# LM4F120E5QR register map
File version: 7944
Registers are 32-bit, read-write, no defined reset value unless marked. A register's access mark holds for its fields unless they carry their own. Offsets are from the block's base; [hi:lo] are bit positions.

## I2C0 — Register map for I2C0 peripheral
Base 0x40020000; register names take the prefix I2C0
Same registers: I2C1 0x40021000 (register names take the prefix I2C1), I2C2 0x40022000 (register names take the prefix I2C2), I2C3 0x40023000 (register names take the prefix I2C3)
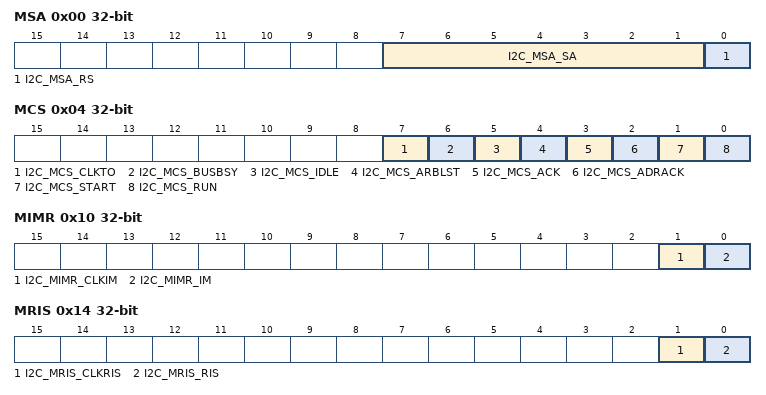
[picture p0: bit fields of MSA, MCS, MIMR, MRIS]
0x00 MSA — I2C Master Slave Address
  [7:1] I2C_MSA_SA — I2C Slave Address
  [0] I2C_MSA_RS — Receive not send
0x04 MCS — I2C Master Control/Status
  [7] I2C_MCS_CLKTO — Clock Timeout Error
  [6] I2C_MCS_BUSBSY — Bus Busy
  [5] I2C_MCS_IDLE — I2C Idle
  [4] I2C_MCS_ARBLST — Arbitration Lost
  [3] I2C_MCS_ACK — Data Acknowledge Enable
  [2] I2C_MCS_ADRACK — Acknowledge Address
  [1] I2C_MCS_START — Generate START
  [0] I2C_MCS_RUN — I2C Master Enable
0x04 MCS (I2C0_ALT view) — I2C Master Control/Status
  [3] I2C_MCS_DATACK — Acknowledge Data
  [2] I2C_MCS_STOP — Generate STOP
  [1] I2C_MCS_ERROR — Error
  [0] I2C_MCS_BUSY — I2C Busy
0x08 MDR — I2C Master Data
  [7:0] I2C_MDR_DATA — Data Transferred
0x0C MTPR — I2C Master Timer Period
  [6:0] I2C_MTPR_TPR — SCL Clock Period
0x10 MIMR — I2C Master Interrupt Mask
  [1] I2C_MIMR_CLKIM — Clock Timeout Interrupt Mask
  [0] I2C_MIMR_IM — Interrupt Mask
0x14 MRIS — I2C Master Raw Interrupt Status
  [1] I2C_MRIS_CLKRIS — Clock Timeout Raw Interrupt Status
  [0] I2C_MRIS_RIS — Raw Interrupt Status
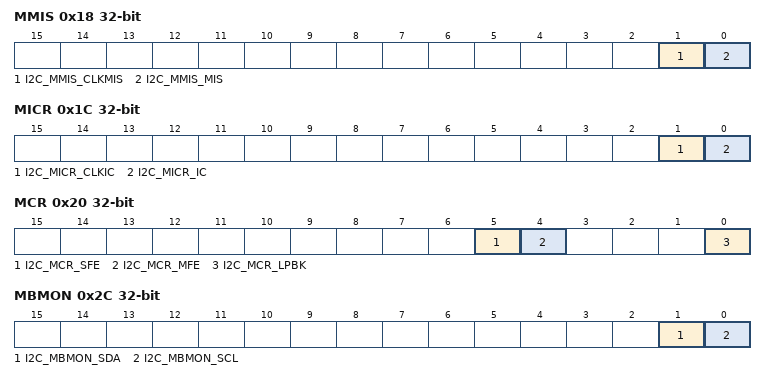
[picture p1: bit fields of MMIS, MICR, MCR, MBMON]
0x18 MMIS — I2C Master Masked Interrupt Status
  [1] I2C_MMIS_CLKMIS — Clock Timeout Masked Interrupt Status
  [0] I2C_MMIS_MIS — Masked Interrupt Status
0x1C MICR wo — I2C Master Interrupt Clear
  [1] I2C_MICR_CLKIC — Clock Timeout Interrupt Clear
  [0] I2C_MICR_IC — Interrupt Clear
0x20 MCR — I2C Master Configuration
  [5] I2C_MCR_SFE — I2C Slave Function Enable
  [4] I2C_MCR_MFE — I2C Master Function Enable
  [0] I2C_MCR_LPBK — I2C Loopback
0x24 MCLKOCNT — I2C Master Clock Low Timeout Count
  [7:0] I2C_MCLKOCNT_CNTL — I2C Master Count
0x2C MBMON — I2C Master Bus Monitor
  [1] I2C_MBMON_SDA — I2C SDA Status
  [0] I2C_MBMON_SCL — I2C SCL Status
0x800 SOAR — I2C Slave Own Address
  [6:0] I2C_SOAR_OAR
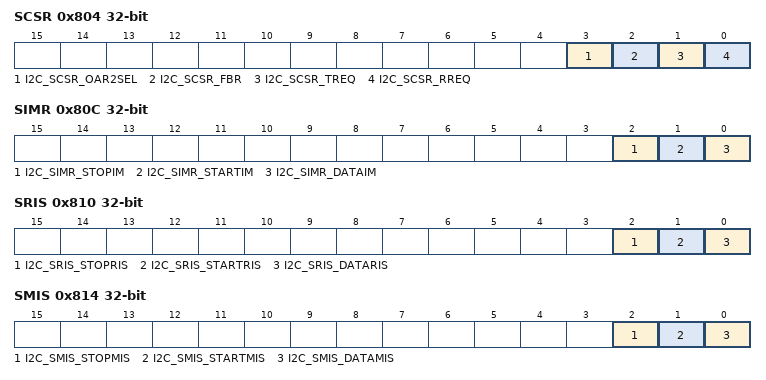
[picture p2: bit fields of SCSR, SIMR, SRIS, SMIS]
0x804 SCSR — I2C Slave Control/Status
  [3] I2C_SCSR_OAR2SEL — OAR2 Address Matched
  [2] I2C_SCSR_FBR — First Byte Received
  [1] I2C_SCSR_TREQ — Transmit Request
  [0] I2C_SCSR_RREQ — Receive Request
0x804 SCSR (I2C0_ALT view) — I2C Slave Control/Status
  [0] I2C_SCSR_DA — Device Active
0x808 SDR — I2C Slave Data
  [7:0] I2C_SDR_DATA — Data for Transfer
0x80C SIMR — I2C Slave Interrupt Mask
  [2] I2C_SIMR_STOPIM — Stop Condition Interrupt Mask
  [1] I2C_SIMR_STARTIM — Start Condition Interrupt Mask
  [0] I2C_SIMR_DATAIM — Data Interrupt Mask
0x810 SRIS — I2C Slave Raw Interrupt Status
  [2] I2C_SRIS_STOPRIS — Stop Condition Raw Interrupt Status
  [1] I2C_SRIS_STARTRIS — Start Condition Raw Interrupt Status
  [0] I2C_SRIS_DATARIS — Data Raw Interrupt Status
0x814 SMIS — I2C Slave Masked Interrupt Status
  [2] I2C_SMIS_STOPMIS — Stop Condition Masked Interrupt Status
  [1] I2C_SMIS_STARTMIS — Start Condition Masked Interrupt Status
  [0] I2C_SMIS_DATAMIS — Data Masked Interrupt Status
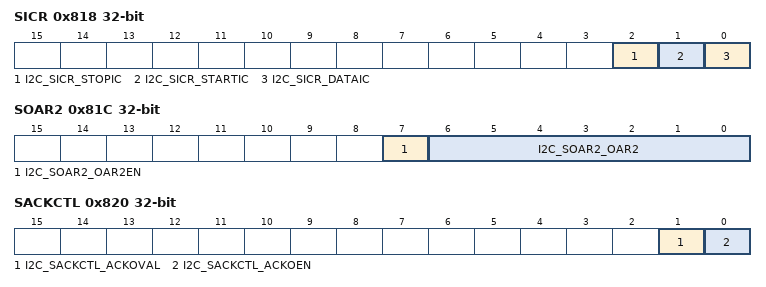
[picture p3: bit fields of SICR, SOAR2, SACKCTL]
0x818 SICR wo — I2C Slave Interrupt Clear
  [2] I2C_SICR_STOPIC — Stop Condition Interrupt Clear
  [1] I2C_SICR_STARTIC — Start Condition Interrupt Clear
  [0] I2C_SICR_DATAIC — Data Interrupt Clear
0x81C SOAR2 — I2C Slave Own Address 2
  [7] I2C_SOAR2_OAR2EN — I2C Slave Own Address 2 Enable
  [6:0] I2C_SOAR2_OAR2 — I2C Slave Own Address 2
0x820 SACKCTL — I2C ACK Control
  [1] I2C_SACKCTL_ACKOVAL — I2C Slave ACK Override Value
  [0] I2C_SACKCTL_ACKOEN — I2C Slave ACK Override Enable
0xFC0 PP — I2C Peripheral Properties
  [0] I2C_PP_HS — High-Speed Capable

## COMP — Register map for COMP peripheral
Base 0x4003C000; register names take the prefix COMP
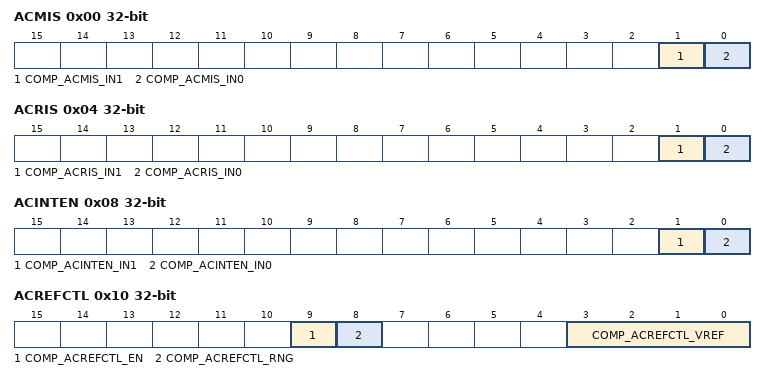
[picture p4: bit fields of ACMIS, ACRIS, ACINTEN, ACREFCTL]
0x00 ACMIS — Analog Comparator Masked Interrupt Status
  [1] COMP_ACMIS_IN1 — Comparator 1 Masked Interrupt Status
  [0] COMP_ACMIS_IN0 — Comparator 0 Masked Interrupt Status
0x04 ACRIS — Analog Comparator Raw Interrupt Status
  [1] COMP_ACRIS_IN1 — Comparator 1 Interrupt Status
  [0] COMP_ACRIS_IN0 — Comparator 0 Interrupt Status
0x08 ACINTEN — Analog Comparator Interrupt Enable
  [1] COMP_ACINTEN_IN1 — Comparator 1 Interrupt Enable
  [0] COMP_ACINTEN_IN0 — Comparator 0 Interrupt Enable
0x10 ACREFCTL — Analog Comparator Reference Voltage Control
  [9] COMP_ACREFCTL_EN — Resistor Ladder Enable
  [8] COMP_ACREFCTL_RNG — Resistor Ladder Range
  [3:0] COMP_ACREFCTL_VREF — Resistor Ladder Voltage Ref
0x20 ACSTAT0 — Analog Comparator Status 0
  [1] COMP_ACSTAT0_OVAL — Comparator Output Value
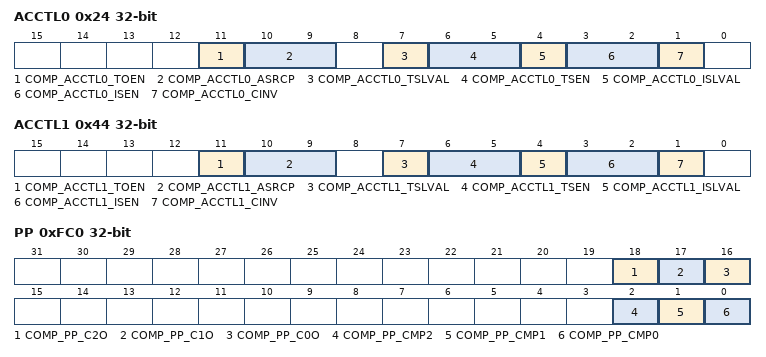
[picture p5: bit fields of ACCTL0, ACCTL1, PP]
0x24 ACCTL0 — Analog Comparator Control 0
  [11] COMP_ACCTL0_TOEN — Trigger Output Enable
  [10:9] COMP_ACCTL0_ASRCP — Analog Source Positive
    0=COMP_ACCTL0_ASRCP_PIN (Pin value of Cn+); 1=COMP_ACCTL0_ASRCP_PIN0 (Pin value of C0+); 2=COMP_ACCTL0_ASRCP_REF (Internal voltage reference (VIREF))
  [7] COMP_ACCTL0_TSLVAL — Trigger Sense Level Value
  [6:5] COMP_ACCTL0_TSEN — Trigger Sense
    0=COMP_ACCTL0_TSEN_LEVEL (Level sense, see TSLVAL); 1=COMP_ACCTL0_TSEN_FALL (Falling edge); 2=COMP_ACCTL0_TSEN_RISE (Rising edge); 3=COMP_ACCTL0_TSEN_BOTH (Either edge)
  [4] COMP_ACCTL0_ISLVAL — Interrupt Sense Level Value
  [3:2] COMP_ACCTL0_ISEN — Interrupt Sense
    0=COMP_ACCTL0_ISEN_LEVEL (Level sense, see ISLVAL); 1=COMP_ACCTL0_ISEN_FALL (Falling edge); 2=COMP_ACCTL0_ISEN_RISE (Rising edge); 3=COMP_ACCTL0_ISEN_BOTH (Either edge)
  [1] COMP_ACCTL0_CINV — Comparator Output Invert
0x40 ACSTAT1 — Analog Comparator Status 1
  [1] COMP_ACSTAT1_OVAL — Comparator Output Value
0x44 ACCTL1 — Analog Comparator Control 1
  [11] COMP_ACCTL1_TOEN — Trigger Output Enable
  [10:9] COMP_ACCTL1_ASRCP — Analog Source Positive
    0=COMP_ACCTL1_ASRCP_PIN (Pin value of Cn+); 1=COMP_ACCTL1_ASRCP_PIN0 (Pin value of C0+); 2=COMP_ACCTL1_ASRCP_REF (Internal voltage reference (VIREF))
  [7] COMP_ACCTL1_TSLVAL — Trigger Sense Level Value
  [6:5] COMP_ACCTL1_TSEN — Trigger Sense
    0=COMP_ACCTL1_TSEN_LEVEL (Level sense, see TSLVAL); 1=COMP_ACCTL1_TSEN_FALL (Falling edge); 2=COMP_ACCTL1_TSEN_RISE (Rising edge); 3=COMP_ACCTL1_TSEN_BOTH (Either edge)
  [4] COMP_ACCTL1_ISLVAL — Interrupt Sense Level Value
  [3:2] COMP_ACCTL1_ISEN — Interrupt Sense
    0=COMP_ACCTL1_ISEN_LEVEL (Level sense, see ISLVAL); 1=COMP_ACCTL1_ISEN_FALL (Falling edge); 2=COMP_ACCTL1_ISEN_RISE (Rising edge); 3=COMP_ACCTL1_ISEN_BOTH (Either edge)
  [1] COMP_ACCTL1_CINV — Comparator Output Invert
0xFC0 PP — Analog Comparator Peripheral Properties
  [18] COMP_PP_C2O — Comparator Output 2 Present
  [17] COMP_PP_C1O — Comparator Output 1 Present
  [16] COMP_PP_C0O — Comparator Output 0 Present
  [2] COMP_PP_CMP2 — Comparator 2 Present
  [1] COMP_PP_CMP1 — Comparator 1 Present
  [0] COMP_PP_CMP0 — Comparator 0 Present
